# IWRL6432 register map
File version: 1.0
CPU: CM4 1.0, other endian, MPU, FPU, 3 interrupt priority bits
Registers are 32-bit, read-write, reset 0x0 unless marked. A register's access mark holds for its fields unless they carry their own. Offsets are from the block's base; [hi:lo] are bit positions; {n}, {i} and the like mark numbered series; 'fields as' and 'values as' point back to an identical list; <NAME> marks a mode.

## APP_CTRL (part 1 of 2)
Base 0x56060000
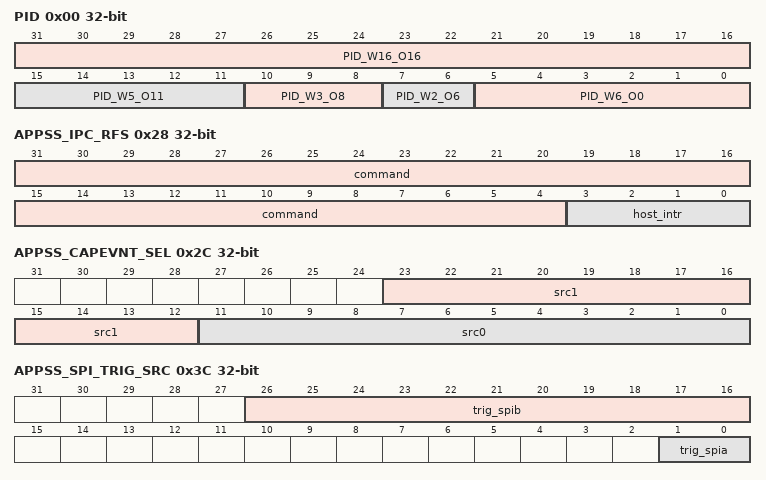
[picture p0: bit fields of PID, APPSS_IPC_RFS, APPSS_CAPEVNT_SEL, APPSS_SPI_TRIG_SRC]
0x00 PID
  [31:16] PID_W16_O16, [15:11] PID_W5_O11, [10:8] PID_W3_O8, [7:6] PID_W2_O6, [5:0] PID_W6_O0
0x04 HW_REG0
  [31:0] hwreg0 — [31:0] HW reserved Regsiter
0x08 HW_REG1
  [31:0] hwreg1 — [31:0] HW reserved Regsiter
0x0C PREVIOUS_NAME
  [31:0] hwreg2 — [31:0] HW reserved Regsiter
{0x4+4i} HW_REG{i} (i=3..7)
  [31:0] hwreg{i} — [31:0] HW reserved Regsiter
0x24 APPSS_SW_INT
  [3:0] pulse — [3:0] Write_pulse bit field: writing 1'b1 to each bit will trigger SW_INT<0-3> respectively to CM4.
0x28 APPSS_IPC_RFS
  [31:4] command — [31:4] Used by software to communicate commands and response. It is 7-bits per interrupt.
  [3:0] host_intr — [3:0] Write_pulse bit field: Writing 1'b1 to each bit will trigger HOST_INTR <0-3> respectively to CM3.
0x2C APPSS_CAPEVNT_SEL
  [23:12] src1 — [23:12] 5:0 : Selects the interrupt to route to RTI Capture event 1 6'd0 : MUXED_FECSS_CHIRPTIMER_CHIRP_START_AND_CHIRP_END 6'd1 : MUXED_FECSS_CHIRPTIMER_BURST_START_AND_BURST_END 6'd2 : FECSS_CHIRPTIMER_FRAME_END 6'd3 : FECSS_FRAMETIMER_FRAME_START 6'd4 : MUXED_FECSS_CHIRP_AVAIL_IRQ_AND_ADC_VALID_START_AND_SYNC_IN 6'd5 : MUXED_FECSS_FRAME_START_OFFSET_INTR_TIME1 6'd6 : FECSS_FRAME_START_OFFSET_INTR_TIME2 6'd7 : FECSS_FRAME_START_OFFSET_INTR_TIME3 6'd8 : FECSS_BURST_START_OFFSET_TIME 11:6: Selects the interrupt to route to WDT Capture event 1 6'd0 : MUXED_FECSS_CHIRPTIMER_CHIRP_START_AND_CHIRP_END 6'd1 : MUXED_FECSS_CHIRPTIMER_BURST_START_AND_BURST_END 6'd2 : FECSS_CHIRPTIMER_FRAME_END 6'd3 : FECSS_FRAMETIMER_FRAME_START 6'd4 : MUXED_FECSS_CHIRP_AVAIL_IRQ_AND_ADC_VALID_START_AND_SYNC_IN 6'd5 : MUXED_FECSS_FRAME_START_OFFSET_INTR_TIME1 6'd6 : FECSS_FRAME_START_OFFSET_INTR_TIME2 6'd7 : FECSS_FRAME_START_OFFSET_INTR_TIME3 6'd8 : FECSS_BURST_START_OFFSET_TIME 6'd9 : FECSS_IPC_RFS_FEC_INTR 1
  [11:0] src0 — [11:0] 5:0 : Selects the interrupt to route to RTI Capture event 0 6'd0 : FECSS_FRAME_START_OFFSET_INTR_TIME3 6'd1 : FECSS_FRAME_START_OFFSET_INTR_TIME2 6'd2 : FECSS_FRAME_START_OFFSET_INTR_TIME1 6'd3 : FECSS_FRAMETIMER_FRAME_START 6'd4 : LIN_INT1 6'd5 : LIN_INT0 6'd6 : MCAN_FE_INT7 6'd7 : MCAN_FE_INT1 6'd8 : MCAN_FE_INT2 6'd9 : MCAN_FE_INT3 6'd10 : MCAN_FE_INT4 6'd11 : MCAN_FE_INT5 6'd12 : MCAN_FE_INT6 6'd13 : MCAN_INT0 6'd14 : MCAN_INT1 6'd15 : SYNC_IN 11:6: Selects the interrupt to route to WDT Capture event 0 6'd0 : MUXED_FECSS_CHIRPTIMER_CHIRP_START_AND_CHIRP_END 6'd1 : MUXED_FECSS_CHIRPTIMER_BURST_START_AND_BURST_END 6'd2 : FECSS_CHIRPTIMER_FRAME_END 6'd3 : FECSS_FRAMETIMER_FRAME_START 6'd4 : MUXED_FECSS_CHIRP_AVAIL_IRQ_AND_ADC_VALID_START_AND_SYNC_IN 6'd5 : MUXED_FECSS_FRAME_START_OFFSET_INTR_TIME1 6'd6 : FECSS_FRAME_START_OFFSET_INTR_TIME2 6'd7 : FECSS_FRAME_START_OFFSET_INTR_TIME3 6'd8 : FECSS_BURST_START_OFFSET_TIME 6'd9 : FECSS_IPC_RFS_FEC_INTR 0
0x30 APPSS_DMA_REQ_SEL
  [31:0] select — [31:0] Reserved for R&D. Do not touch
0x34 APPSS_DMA1_REQ_SEL
  [31:0] select — [31:0] Reserved for R&D. Do not touch
0x38 APPSS_IRQ_REQ_SEL
  [31:0] select — [31:0] Configuration register APPSS_IRQ_REQ_SEL is used to select the interrupt for CM4. Below are the bit definitions 0 : 0x0 = Map 0th IRQ from compare block of RTI (RTI1) to IRQ43 : 0x1 = Map 0th IRQ from compare block of WDT (RTI2) to IRQ43 1 : 0x0 = Map 1st IRQ from compare block of RTI (RTI1) to IRQ44 : 0x1 = Map 1st IRQ from compare block of WDT (RTI2) to IRQ44 2 : 0x0 = Map 2nd IRQ from compare block of RTI (RTI1) to IRQ45 : 0x1 = Map 2nd IRQ from compare block of WDT (RTI2) to IRQ45 3 : 0x0 = Map 3rd IRQ from compare block of RTI (RTI1) to IRQ46 : 0x1 = Map 3rd IRQ from compare block of WDT (RTI2) to IRQ46 5:4 : 0x00 = Selects time base IRQ from RTI (RTI1) to IRQ47 : 0x01 = Selects time base IRQ from WDT (RTI2) to IRQ47 : 0x10 = Selects gpadc_ifm_done to IRQ47 : 0x11 = Reserved 7:6 : 0x00 = Selects capture event 0 of RTI to IRQ48 and Selects capture event 1 of IRQ from RTI to IRQ49 : 0x01 = Selects capture event 0 of WDT to IRQ48 and Selects capture event 1 of IRQ from WDT to IRQ49 : 0x10 = Selects PWM Interrupt 0 to IRQ48 and PWM Interrupt 1 to IRQ49 : 0x11 = Selects OVL_REQ of RTI (RTI1) to IRQ48 and OVL_REQ of WDT to IRQ49 8 : 0x0 = mcan_fe_int7 connected to IRQ29 : 0x1 = debugss txdata_available interrupt connected to IRQ29. 9 : 0x0 = Used for TPPCA trigger. Dma read interrupt of SPI1/A channel routed to TPCCA (DMA) trigger 62 : 0x1 = Used for TPPCA trigger. dma read interrupt of SPI2/B channel routed to TPCCA (DMA) trigger 62 10 : 0x0 = Used for TPPCA trigger. dma write interrupt of SPI1/A channel routed to TPCCA (DMA) trigger 63 : 0x1 = Used for TPPCA trigger. dma write interrupt of SPI2/B channel routed to TPCCA (DMA) trigger 63 11 : 0x0 = Timing Engine Chirptimer_chirp_start to IRQ30 : 0x1 = Timing Engine Chirptimer_chirp_end to IRQ30 12 : 0x0 = Timing Engine Chirptimer_burst_start to IRQ31 : 0x1 = Timing Engine Chirptimer_burst_end to IRQ31 14:13: 0x00 = chirp_avail_irq to IRQ34 : 0x01 = adc_valid_start to IRQ34 : 0x10 = SYNC_in to IRQ34 15 : Reserved 16 : 0x0 = mcan_fe_int6 connected to IRQ28 : 0x1 = spi2_int_req connected to IRQ28 18:17: 0x00 = DCC_DONE Interrupt connected to IRQ12 : 0x01 = CM4 LBIST Interrupt connected to IRQ12 : 0x10 = CM3 LBIST Interrupt connected to IRQ12 : 0x11 = TOP PBIST Interrupt connected to IRQ12 20:19: 0x00 = I2C_INT Interrupt connected to IRQ19 : 0x01 = CM4 LBIST Interrupt connected to IRQ19 : 0x10 = CM3 LBIST Interrupt connected to IRQ19 : 0x11 = TOP PBIST Interrupt connected to IRQ19 21 : 0x0 = APPSS_TPCC1_ERRAGG connected to IRQ16 : 0x1 = CTI_TRIGOUT2 connected to IRQ16 22 : 0x0 = APPSS_TPCC2_ERRAGG connected to IRQ18 : 0x1 = CTI_TRIGOUT3 connected to IRQ18
0x3C APPSS_SPI_TRIG_SRC
  [26:16] trig_spib — [26:16] RESERVED
  [1:0] trig_spia — [1:0] RESERVED
{0x34+0xC*i} APPSS_RAM{i}A_MEM_INIT (i=1..3)
  [0] mem_init — [0:0] Write_pulse bit field: Writing 1'b1 will start initialization of APPSS_RAM{i} partion0 bank. Value in each row is initialized to 0x0C_0000_0000
{0x38+0xC*i} APPSS_RAM{i}A_MEM_INIT_DONE (i=1..3)
  [0] mem_init_done — [0:0] This field will be high once initialization of APPSS_RAM{i} partion0 banks is finished. Writing '1' would clear the bit.
{0x3C+0xC*i} APPSS_RAM{i}A_MEM_INIT_STATUS (i=1..3)
  [0] mem_status — [0:0] 1'b0: No initialization is happening for APPSS_RAM{i} partion0 bank 1'b1: Initialization is in progress for APPSS_RAM{i} partion0 bank
0x64 HWASS_SHRD_RAM0_MEM_INIT
  [0] mem_init — [0:0] Write_pulse bit field: Writing 1'b1 will start initializing the HWASS Shared RAM parition0. Value in each row is initialized to 0x0
0x68 HWASS_SHRD_RAM0_MEM_INIT_DONE
  [0] mem_init_done — [0:0] This field will be high once intialization of HWASS Shared RAM parition0 is finished. Writing '1' would clear the bit
0x6C HWASS_SHRD_RAM0_MEM_INIT_STATUS
  [0] mem_status — [0:0] 1'b0: No initialization is happening for HWASS Shared RAM parition0 1'b1: Initialization is in progress for HWASS Shared RAM parition0
0x70 HWASS_SHRD_RAM1_MEM_INIT
  [0] mem_init — [0:0] Write_pulse bit field: Writing 1'b1 will start initializing the HWASS Shared RAM parition1. Value in each row is initialized to 0x0
0x74 HWASS_SHRD_RAM1_MEM_INIT_DONE
  [0] mem_init_done — [0:0] This field will be high once intialization of HWASS Shared RAM parition1 is finished. Writing '1' would clear the bit
0x78 HWASS_SHRD_RAM1_MEM_INIT_STATUS
  [0] mem_status — [0:0] 1'b0: No initialization is happening for HWASS Shared RAM parition1 1'b1: Initialization is in progress for HWASS Shared RAM parition1
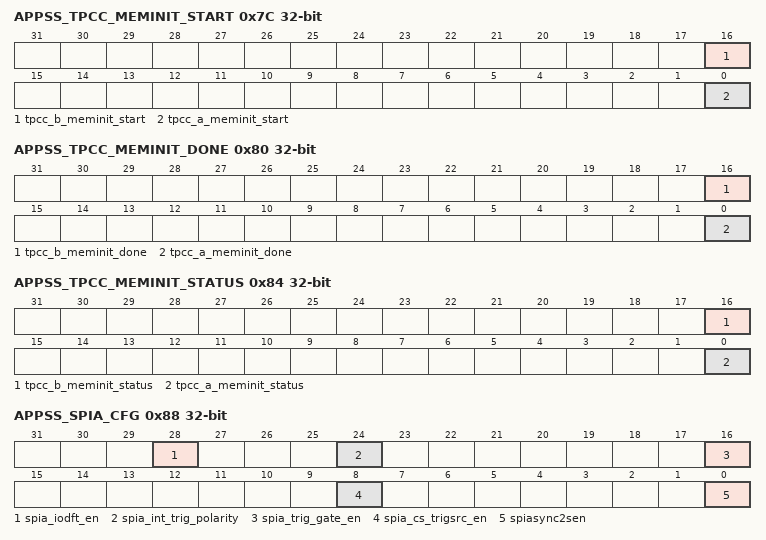
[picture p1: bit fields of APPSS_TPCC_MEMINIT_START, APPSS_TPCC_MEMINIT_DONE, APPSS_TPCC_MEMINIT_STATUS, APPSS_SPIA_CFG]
0x7C APPSS_TPCC_MEMINIT_START
  [16] tpcc_b_meminit_start — [16:16] Write_pulse bit field: Writing 1'b1 will start initializing the TPCCB
  [0] tpcc_a_meminit_start — [0:0] Write_pulse bit field: Writing 1'b1 will start initializing the TPCCA
0x80 APPSS_TPCC_MEMINIT_DONE
  [16] tpcc_b_meminit_done — [16:16] This field will be high once intialization of TPCCB is finished. Writing '1' would clear the bit
  [0] tpcc_a_meminit_done — [0:0] This field will be high once intialization of TPCCA is finished. Writing '1' would clear the bit
0x84 APPSS_TPCC_MEMINIT_STATUS
  [16] tpcc_b_meminit_status — [16:16] 1'b0: No initialization is happening for TPCCA 1'b1: Initialization is in progress for TPCCB
  [0] tpcc_a_meminit_status — [0:0] 1'b0: No initialization is happening for TPCCA 1'b1: Initialization is in progress for TPCCB
0x88 APPSS_SPIA_CFG
  [28] spia_iodft_en — [28:28] 1: Enable loop back of MOSI to MISO - Master mode Enable loop back of MISO to MOSI - Slave mode
  [24] spia_int_trig_polarity — [24:24] SPIA trigger source polarity select. 0 - Polarity 0, 1 -Polarity 1
  [16] spia_trig_gate_en — [16:16] When set the TRIGGER s are un-gated only when chip-select is active
  [8] spia_cs_trigsrc_en — [8:8] MIBSPIB CS Trigger SRC enable 1 : Use CS as trigger source
  [0] spiasync2sen — [0:0] Donot touch the field. Used as Tie-off for IP-config.
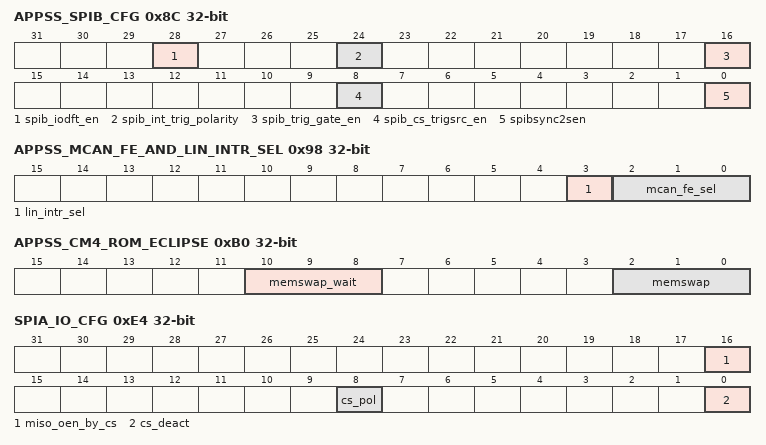
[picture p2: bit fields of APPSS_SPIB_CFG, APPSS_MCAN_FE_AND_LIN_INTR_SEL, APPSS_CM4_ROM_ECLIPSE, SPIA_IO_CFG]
0x8C APPSS_SPIB_CFG
  [28] spib_iodft_en — [28:28] 1: Enable loop back of MOSI to MISO - Master mode Enable loop back of MISO to MOSI - Slave mode
  [24] spib_int_trig_polarity — [24:24] SPIB trigger source polarity select. 0 - Polarity 0, 1 -Polarity 1
  [16] spib_trig_gate_en — [16:16] When set the TRIGGER s are un-gated only when chip-select is active
  [8] spib_cs_trigsrc_en — [8:8] MIBSPIB CS Trigger SRC enable 1 : Use CS as trigger source
  [0] spibsync2sen — [0:0] Donot touch the field. Used as Tie-off for IP-config.
0x90 APPSS_EPWM_CFG
  [31:0] epwm_config — [31:0] bit0: SW syncin for EPWM1 bit1: SW syncin for EPWM2 bit2: SW syncin for EPWM3 bit8:9 : select bits for EPWM1 '0' : external syncin '1' : reserved '2' : sw syncin '3' : reserved bit10:11 : select bits for EPWM2 '0' : external syncin '1' : chained from EPWM1 '2' : sw syncin '3' : reserved bit12:13 : select bits for EPWM3 '0' : external syncin '1' : chained from EPWM2 '2' : sw syncin '3' : reserved bit24:TBCLKEN for EPWM1 bit25:TBCLKEN for EPWM2 bit26:TBCLKEN for EPWM3
0x94 RESERVED
  [31:0] gio_config — [31:0] bit0 : writing '1' will slect negedge for pulse generation of GIO_PAD_INT0 to IRQ bit1 : writing '1' will slect negedge for pulse generation of GIO_PAD_INT1to IRQ bit2: writing '1' will slect negedge for pulse generation of GIO_PAD_INT2 to IRQ bit3 : writing '1' will slect negedge for pulse generation of GIO_PAD_INT3 to IRQ bit4 : writing '1' will slect negedge for pulse generation of GIO_PAD_INT4 to IRQ bit5 : writing '1' will slect negedge for pulse generation of GIO_PAD_INT5 to IRQ bit6 : writing '1' will slect negedge for pulse generation of GIO_PAD_INT6 to IRQ bit7 : writing '1' will slect negedge for pulse generation of GIO_PAD_INT7 to IRQ
0x98 APPSS_MCAN_FE_AND_LIN_INTR_SEL
  [3] lin_intr_sel — [3:3] Writing a value would select the LIN interrupt in combination with HW_SYNC_IN and CAN filter events for Frame timer 0 : 0th interrupt bit is selected 1 : 1st interrupt bit is selected
  [2:0] mcan_fe_sel — [2:0] Writing a value 'N' would select Nth filter interrupt combination with SYNC_IN(IO) for triggering timing engine Example: writing 3'd<1-7> selects MCAN_FE_INT<1-7> respectively
0x9C APPSS_MCANA_INT_CLR
  [31:0] mcan_int_clr — [31:0] Interrupt Clear for 32 MCANSS TX DMA interrupts. Writing 1'b1 to bit<0-31> clears interrupt source <0-31> respectively in MCANA
0xA0 APPSS_MCANA_INT_MASK
  [31:0] mcan_int_mask — [31:0] Interrupt Mask for 32 MCANSS TX DMA interrupts. Writing 1'b1 to bit<0-31> masks interrupt source <0-31> respectively in MCANA
0xA4 APPSS_MCANA_INT_STAT
  [31:0] mcan_int_status — [31:0] Interrupt status for 32 MCANSS TX DMA interrupts. 1'b1 in bit<0-31> gives pending status for interrupt <0-31> respectively in MCANA
0xA8 APPSS_CM4_GLOBAL_CONFIG
  [0] teinit — [0:0] Reserved
0xAC RESERVED1
  [31:0] res — [31:0] reserved
0xB0 APPSS_CM4_ROM_ECLIPSE
  [10:8] memswap_wait — [10:8] writing 3'b111 ensures ROM-Eclipsing happens only after CPU sys reset. Orelse it will be a immediate change.
  [2:0] memswap — [2:0] writing '111' ensures eclipsing of CPU_ROM immediately if memswap_wait is not set. If memswap_wait is set then ROM is eclipsed after CPU sys reset assertion.
0xB4 APPSS_CM4_STATUS_REG
  [0] memswap — [0:0] reading 1: confirms ROM is Eclipsed from with RAM for the CPU.
0xB8 APPSS_AHB_CTRL
  [0] cpu0_ahb_init — [0:0] Ti internal Register. Modifying this register is not recommended Signal decides whehter ahb interface is enabled or not.
{0xBC+4i} ESM_GATING{i} (i=0..3)
  [31:0] esm_gating — [31:0] bit3:0 : writing '000' will ungate the ESM_GRP2_ERROR_{8i} bit7:4 : writing '000' will ungate the ESM_GRP2_ERROR_{8i+1} bit31:28 : writing '000' will ungate the ESM_GRP2_ERROR_{8i+7}
{0xBC+4i} ESM_GATING{i} (i=4..7)
  [31:0] esm_gating — [31:0] bit3:0 : writing '000' will ungate the ESM_GRP3_ERROR_{8i-32} bit7:4 : writing '000' will ungate the ESM_GRP3_ERROR_{8i-31} bit31:28 : writing '000' will ungate the ESM_GRP3_ERROR_{8i-25}
0xDC APPSS_CM4_HALT
  [2:0] halt — [2:0] RESERVED
0xE0 APPSS_CM4_EVENT
  [2:0] cpu0_event — [2:0] Reserved Register for R & D
0xE4 SPIA_IO_CFG
  [16] miso_oen_by_cs — [16:16] RESERVED
  [8] cs_pol — [8:8] RESERVED
  [0] cs_deact — [0:0] RESERVED
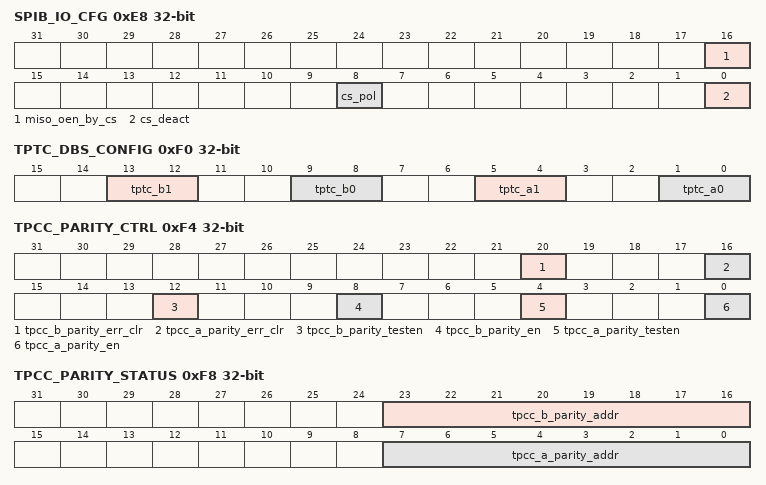
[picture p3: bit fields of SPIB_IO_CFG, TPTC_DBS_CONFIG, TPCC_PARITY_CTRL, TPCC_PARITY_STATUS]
0xE8 SPIB_IO_CFG
  fields as SPIA_IO_CFG
0xEC SPI_HOST_IRQ
  [0] host_irq — [0:0] RESERVED
0xF0 TPTC_DBS_CONFIG
  [13:12] tptc_b1 — [13:12] Default burst size tieoff value for TPTC_B1
  [9:8] tptc_b0 — [9:8] Default burst size tieoff value for TPTC_B0
  [5:4] tptc_a1 — [5:4] Default burst size tieoff value for TPTC_A1
  [1:0] tptc_a0 — [1:0] Default burst size tieoff value for TPTC_A0
0xF4 TPCC_PARITY_CTRL
  [20] tpcc_b_parity_err_clr — [20:20] Write pulse bit field: parity clear bit. Writing 1'b1 will clear the tpcc_b_parity_addr
  [16] tpcc_a_parity_err_clr — [16:16] Write pulse bit field: parity clear bit. Writing 1'b1 will clear the tpcc_a_parity_addr
  [12] tpcc_b_parity_testen — [12:12] parity test enable for tpcc b
  [8] tpcc_b_parity_en — [8:8] parity en for tpcc b
  [4] tpcc_a_parity_testen — [4:4] parity test enable for tpcc a
  [0] tpcc_a_parity_en — [0:0] writing 1'b1 enables parity for TPCC_A
0xF8 TPCC_PARITY_STATUS
  [23:16] tpcc_b_parity_addr — [23:16] address where parity error happened for tpccb
  [7:0] tpcc_a_parity_addr — [7:0] address where parity error happened for tpcca
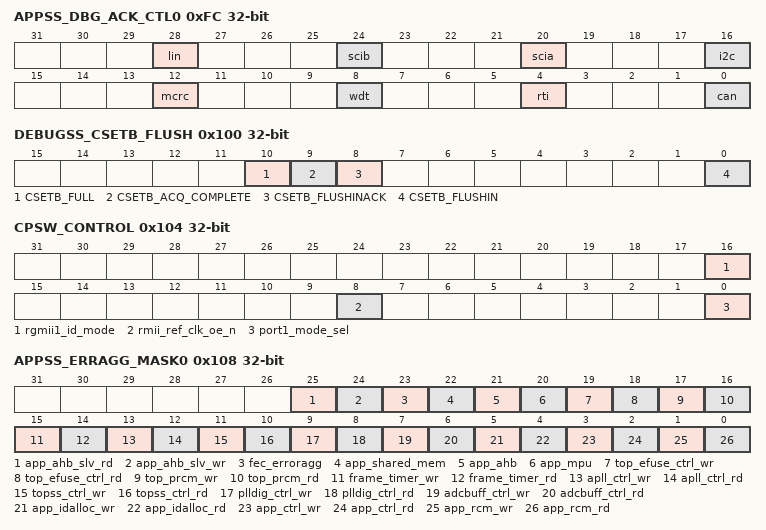
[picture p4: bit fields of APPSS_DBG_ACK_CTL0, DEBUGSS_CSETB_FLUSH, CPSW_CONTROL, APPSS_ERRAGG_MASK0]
0xFC APPSS_DBG_ACK_CTL0
  [28] lin — [28:28] Enable Suspend control for the peripheral. 0 :Peripheral not suspended along with processor 1: Peripehal Suspended along with procesor
  [24] scib — [24:24] Enable Suspend control for the peripheral. 0 :Peripheral not suspended along with processor 1: Peripehal Suspended along with procesor
  [20] scia — [20:20] Enable Suspend control for the peripheral. 0 :Peripheral not suspended along with processor 1: Peripehal Suspended along with procesor
  [16] i2c — [16:16] Enable Suspend control for the peripheral. 0 :Peripheral not suspended along with processor 1: Peripehal Suspended along with procesor
  [12] mcrc — [12:12] Enable Suspend control for the peripheral. 0 :Peripheral not suspended along with processor 1: Peripehal Suspended along with procesor
  [8] wdt — [8:8] Enable Suspend control for the peripheral. 0 :Peripheral not suspended along with processor 1: Peripehal Suspended along with procesor
  [4] rti — [4:4] Enable Suspend control for the peripheral. 0 :Peripheral not suspended along with processor 1: Peripehal Suspended along with procesor
  [0] can — [0:0] Enable Suspend control for the peripheral. 0 :Peripheral not suspended along with processor 1: Peripehal Suspended along with procesor
0x100 DEBUGSS_CSETB_FLUSH
  [10] CSETB_FULL — [10:10] RESERVED
  [9] CSETB_ACQ_COMPLETE — [9:9] RESERVED
  [8] CSETB_FLUSHINACK — [8:8] RESERVED
  [0] CSETB_FLUSHIN — [0:0] RESERVED
0x104 CPSW_CONTROL
  [16] rgmii1_id_mode — [16:16] Reserved
  [8] rmii_ref_clk_oe_n — [8:8] Reserved
  [0] port1_mode_sel — [0:0] Reserved
0x108 APPSS_ERRAGG_MASK0
  [25] app_ahb_slv_rd — [25:25] Mask Interrupt from AHB slaves to aggregated Interrupt APPSS_ACCESS_ERRAGG 1 : Interrupt is Masked 0 : Interrupt is Unmasked
  [24] app_ahb_slv_wr — [24:24] Mask Interrupt from AHB slaves to aggregated Interrupt APPSS_ACCESS_ERRAGG 1 : Interrupt is Masked 0 : Interrupt is Unmasked
  [23] fec_erroragg — [23:23] Mask Interrupt from FEC_ERRORAGG to aggregated Interrupt APPSS_ACCESS_ERRAGG 1 : Interrupt is Masked 0 : Interrupt is Unmasked
  [22] app_shared_mem — [22:22] Mask Interrupt from APP_SHARED_MEM to aggregated Interrupt APPSS_ACCESS_ERRAGG 1 : Interrupt is Masked 0 : Interrupt is Unmasked
  [21] app_ahb — [21:21] Mask Interrupt from APP_AHB to aggregated Interrupt APPSS_ACCESS_ERRAGG 1 : Interrupt is Masked 0 : Interrupt is Unmasked
  [20] app_mpu — [20:20] Mask Interrupt from APP_MPU to aggregated Interrupt APPSS_ACCESS_ERRAGG 1 : Interrupt is Masked 0 : Interrupt is Unmasked
  [19] top_efuse_ctrl_wr — [19:19] Mask Interrupt from TOP_EFUSE_CTRL to aggregated Interrupt APPSS_ACCESS_ERRAGG 1 : Interrupt is Masked 0 : Interrupt is Unmasked
  [18] top_efuse_ctrl_rd — [18:18] Mask Interrupt from FEC_ERRORAGG to aggregated Interrupt APPSS_ACCESS_ERRAGG 1 : Interrupt is Masked 0 : Interrupt is Unmasked
  [17] top_prcm_wr — [17:17] Mask Interrupt from TOP_PRCM to aggregated Interrupt APPSS_ACCESS_ERRAGG 1 : Interrupt is Masked 0 : Interrupt is Unmasked
  [16] top_prcm_rd — [16:16] Mask Interrupt from TOP_PRCM to aggregated Interrupt APPSS_ACCESS_ERRAGG 1 : Interrupt is Masked 0 : Interrupt is Unmasked
  [15] frame_timer_wr — [15:15] Mask Interrupt from FRAME_TIMER to aggregated Interrupt APPSS_ACCESS_ERRAGG 1 : Interrupt is Masked 0 : Interrupt is Unmasked
  [14] frame_timer_rd — [14:14] Mask Interrupt from FRAME_TIMER to aggregated Interrupt APPSS_ACCESS_ERRAGG 1 : Interrupt is Masked 0 : Interrupt is Unmasked
  [13] apll_ctrl_wr — [13:13] Mask Interrupt from APLL_CTRL to aggregated Interrupt APPSS_ACCESS_ERRAGG 1 : Interrupt is Masked 0 : Interrupt is Unmasked
  [12] apll_ctrl_rd — [12:12] Mask Interrupt from APLL_CTRL to aggregated Interrupt APPSS_ACCESS_ERRAGG 1 : Interrupt is Masked 0 : Interrupt is Unmasked
  [11] topss_ctrl_wr — [11:11] Mask Interrupt from TOPSS_CTRL to aggregated Interrupt APPSS_ACCESS_ERRAGG 1 : Interrupt is Masked 0 : Interrupt is Unmasked
  [10] topss_ctrl_rd — [10:10] Mask Interrupt from TOPSS_CTRL to aggregated Interrupt APPSS_ACCESS_ERRAGG 1 : Interrupt is Masked 0 : Interrupt is Unmasked
  [9] plldig_ctrl_wr — [9:9] Mask Interrupt from PLLDIG_CTRL to aggregated Interrupt APPSS_ACCESS_ERRAGG 1 : Interrupt is Masked 0 : Interrupt is Unmasked
  [8] plldig_ctrl_rd — [8:8] Mask Interrupt from PLLDIG_CTRL to aggregated Interrupt APPSS_ACCESS_ERRAGG 1 : Interrupt is Masked 0 : Interrupt is Unmasked
  [7] adcbuff_ctrl_wr — [7:7] Mask Interrupt from ADCBUFF_CTRL to aggregated Interrupt APPSS_ACCESS_ERRAGG 1 : Interrupt is Masked 0 : Interrupt is Unmasked
  [6] adcbuff_ctrl_rd — [6:6] Mask Interrupt from ADCBUFF_CTRL to aggregated Interrupt APPSS_ACCESS_ERRAGG 1 : Interrupt is Masked 0 : Interrupt is Unmasked
  [5] app_idalloc_wr — [5:5] Mask Interrupt from APP_IDALLOC to aggregated Interrupt APPSS_ACCESS_ERRAGG 1 : Interrupt is Masked 0 : Interrupt is Unmasked
  [4] app_idalloc_rd — [4:4] Mask Interrupt from APP_IDALLOC to aggregated Interrupt APPSS_ACCESS_ERRAGG 1 : Interrupt is Masked 0 : Interrupt is Unmasked
  [3] app_ctrl_wr — [3:3] Mask Interrupt from APP_CTRL to aggregated Interrupt APPSS_ACCESS_ERRAGG 1 : Interrupt is Masked 0 : Interrupt is Unmasked
  [2] app_ctrl_rd — [2:2] Mask Interrupt from APP_CTRL to aggregated Interrupt APPSS_ACCESS_ERRAGG 1 : Interrupt is Masked 0 : Interrupt is Unmasked
  [1] app_rcm_wr — [1:1] Mask Interrupt from APP_RCM to aggregated Interrupt APPSS_ACCESS_ERRAGG 1 : Interrupt is Masked 0 : Interrupt is Unmasked
  [0] app_rcm_rd — [0:0] Mask Interrupt from APP_RCM to aggregated Interrupt APPSS_ACCESS_ERRAGG 1 : Interrupt is Masked 0 : Interrupt is Unmasked
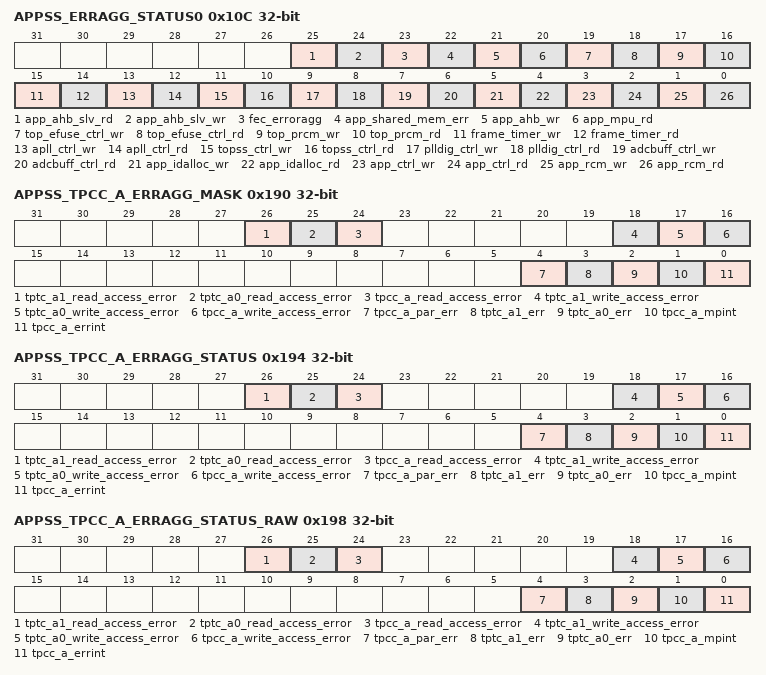
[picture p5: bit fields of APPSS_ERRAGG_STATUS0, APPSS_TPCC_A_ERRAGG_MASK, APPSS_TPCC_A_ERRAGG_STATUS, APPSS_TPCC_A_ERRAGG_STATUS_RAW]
0x10C APPSS_ERRAGG_STATUS0
  [25] app_ahb_slv_rd — [25:25] Status of Interrupt from AHB_SLAVE Set only if Interupt is unmasked in APPSS_ERRAGG_MASK0 Wrie 0x1 to clear this interrupt.
  [24] app_ahb_slv_wr — [24:24] Status of Interrupt from AHB_SLAVE Set only if Interupt is unmasked in APPSS_ERRAGG_MASK0 Wrie 0x1 to clear this interrupt.
  [23] fec_erroragg — [23:23] Status of Interrupt from FEC_ERRORAGG Set only if Interupt is unmasked in APPSS_ERRAGG_MASK0 Wrie 0x1 to clear this interrupt.
  [22] app_shared_mem_err — [22:22] Status of Interrupt from APP_SHARED_MEM Set only if Interupt is unmasked in APPSS_ERRAGG_MASK0 Wrie 0x1 to clear this interrupt.
  [21] app_ahb_wr — [21:21] Status of Interrupt from APP_AHB Set only if Interupt is unmasked in APPSS_ERRAGG_MASK0 Wrie 0x1 to clear this interrupt.
  [20] app_mpu_rd — [20:20] Status of Interrupt from APP_MPU Set only if Interupt is unmasked in APPSS_ERRAGG_MASK0 Wrie 0x1 to clear this interrupt.
  [19] top_efuse_ctrl_wr — [19:19] Status of Interrupt from TOP_EFUSE_CTRL Set only if Interupt is unmasked in APPSS_ERRAGG_MASK0 Wrie 0x1 to clear this interrupt.
  [18] top_efuse_ctrl_rd — [18:18] Status of Interrupt from TOP_EFUSE_CTRL Set only if Interupt is unmasked in APPSS_ERRAGG_MASK0 Wrie 0x1 to clear this interrupt.
  [17] top_prcm_wr — [17:17] Status of Interrupt from TOP_PRCM Set only if Interupt is unmasked in APPSS_ERRAGG_MASK0 Wrie 0x1 to clear this interrupt.
  [16] top_prcm_rd — [16:16] Status of Interrupt from TOP_PRCM Set only if Interupt is unmasked in APPSS_ERRAGG_MASK0 Wrie 0x1 to clear this interrupt.
  [15] frame_timer_wr — [15:15] Status of Interrupt from FRAME_TIMER Set only if Interupt is unmasked in APPSS_ERRAGG_MASK0 Wrie 0x1 to clear this interrupt.
  [14] frame_timer_rd — [14:14] Status of Interrupt from FRAME_TIMER Set only if Interupt is unmasked in APPSS_ERRAGG_MASK0 Wrie 0x1 to clear this interrupt.
  [13] apll_ctrl_wr — [13:13] Status of Interrupt from APLL_CTRL Set only if Interupt is unmasked in APPSS_ERRAGG_MASK0 Wrie 0x1 to clear this interrupt.
  [12] apll_ctrl_rd — [12:12] Status of Interrupt from APLL_CTRL Set only if Interupt is unmasked in APPSS_ERRAGG_MASK0 Wrie 0x1 to clear this interrupt.
  [11] topss_ctrl_wr — [11:11] Status of Interrupt from TOPSS_CTRL Set only if Interupt is unmasked in APPSS_ERRAGG_MASK0 Wrie 0x1 to clear this interrupt.
  [10] topss_ctrl_rd — [10:10] Status of Interrupt from TOPSS_CTRL Set only if Interupt is unmasked in APPSS_ERRAGG_MASK0 Wrie 0x1 to clear this interrupt.
  [9] plldig_ctrl_wr — [9:9] Status of Interrupt from PLLDIG_CTRL Set only if Interupt is unmasked in APPSS_ERRAGG_MASK0 Wrie 0x1 to clear this interrupt.
  [8] plldig_ctrl_rd — [8:8] Status of Interrupt from PLLDIG_CTRL Set only if Interupt is unmasked in APPSS_ERRAGG_MASK0 Wrie 0x1 to clear this interrupt.
  [7] adcbuff_ctrl_wr — [7:7] Status of Interrupt from ADCBUFF_CTRL Set only if Interupt is unmasked in APPSS_ERRAGG_MASK0 Wrie 0x1 to clear this interrupt.
  [6] adcbuff_ctrl_rd — [6:6] Status of Interrupt from ADCBUFF_CTRL Set only if Interupt is unmasked in APPSS_ERRAGG_MASK0 Wrie 0x1 to clear this interrupt.
  [5] app_idalloc_wr — [5:5] Status of Interrupt from APP_IDALLOC Set only if Interupt is unmasked in APPSS_ERRAGG_MASK0 Wrie 0x1 to clear this interrupt.
  [4] app_idalloc_rd — [4:4] Status of Interrupt from APP_IDALLOC Set only if Interupt is unmasked in APPSS_ERRAGG_MASK0 Wrie 0x1 to clear this interrupt.
  [3] app_ctrl_wr — [3:3] Status of Interrupt from APP_CTRL Set only if Interupt is unmasked in APPSS_ERRAGG_MASK0 Wrie 0x1 to clear this interrupt.
  [2] app_ctrl_rd — [2:2] Status of Interrupt from APP_CTRL Set only if Interupt is unmasked in APPSS_ERRAGG_MASK0 Wrie 0x1 to clear this interrupt.
  [1] app_rcm_wr — [1:1] Status of Interrupt from APP_RCM Set only if Interupt is unmasked in APPSS_ERRAGG_MASK0 Wrie 0x1 to clear this interrupt.
  [0] app_rcm_rd — [0:0] Status of Interrupt from APP_RCM Set only if Interupt is unmasked in APPSS_ERRAGG_MASK0 Wrie 0x1 to clear this interrupt.
0x190 APPSS_TPCC_A_ERRAGG_MASK
  [26] tptc_a1_read_access_error — [26:26] Mask Error from TPTC_A1 to aggregated Error TPCC_A_ERRAGG 1 : Error is Masked 0 : Error is Unmasked
  [25] tptc_a0_read_access_error — [25:25] Mask Error from TPTC_A0 to aggregated Error TPCC_A_ERRAGG 1 : Error is Masked 0 : Error is Unmasked
  [24] tpcc_a_read_access_error — [24:24] Mask Error from TPCC_A to aggregated Error TPCC_A_ERRAGG 1 : Error is Masked 0 : Error is Unmasked
  [18] tptc_a1_write_access_error — [18:18] Mask Error from TPTC_A1 to aggregated Error TPCC_A_ERRAGG 1 : Error is Masked 0 : Error is Unmasked
  [17] tptc_a0_write_access_error — [17:17] Mask Error from TPTC_A0 to aggregated Error TPCC_A_ERRAGG 1 : Error is Masked 0 : Error is Unmasked
  [16] tpcc_a_write_access_error — [16:16] Mask Error from TPCC_A to aggregated Error TPCC_A_ERRAGG 1 : Error is Masked 0 : Error is Unmasked
  [4] tpcc_a_par_err — [4:4] Mask Error from TPCC_A to aggregated Error TPCC_A_ERRAGG 1 : Error is Masked 0 : Error is Unmasked
  [3] tptc_a1_err — [3:3] Mask Error from TPTC_A1 to aggregated Error TPCC_A_ERRAGG 1 : Error is Masked 0 : Error is Unmasked
  [2] tptc_a0_err — [2:2] Mask Error from TPTC_A0 to aggregated Error TPCC_A_ERRAGG 1 : Error is Masked 0 : Error is Unmasked
  [1] tpcc_a_mpint — [1:1] Mask Error from TPCC_A to aggregated Error TPCC_A_ERRAGG 1 : Error is Masked 0 : Error is Unmasked
  [0] tpcc_a_errint — [0:0] Mask Error from TPCC_A to aggregated Error TPCC_A_ERRAGG 1 : Error is Masked 0 : Error is Unmasked
0x194 APPSS_TPCC_A_ERRAGG_STATUS
  [26] tptc_a1_read_access_error — [26:26] Status of Error from TPTC_A1. Set only if Interupt is unmasked in TPCC_A_ERRAGG_MASK Wrie 0x1 to clear this Error.
  [25] tptc_a0_read_access_error — [25:25] Status of Error from TPTC_A0. Set only if Interupt is unmasked in TPCC_A_ERRAGG_MASK Wrie 0x1 to clear this Error.
  [24] tpcc_a_read_access_error — [24:24] Status of Error from TPCC_A. Set only if Interupt is unmasked in TPCC_A_ERRAGG_MASK Wrie 0x1 to clear this Error.
  [18] tptc_a1_write_access_error — [18:18] Status of Error from TPTC_A1. Set only if Interupt is unmasked in TPCC_A_ERRAGG_MASK Wrie 0x1 to clear this Error.
  [17] tptc_a0_write_access_error — [17:17] Status of Error from TPTC_A0. Set only if Interupt is unmasked in TPCC_A_ERRAGG_MASK Wrie 0x1 to clear this Error.
  [16] tpcc_a_write_access_error — [16:16] Status of Error from TPCC_A. Set only if Interupt is unmasked in TPCC_A_ERRAGG_MASK Wrie 0x1 to clear this Error.
  [4] tpcc_a_par_err — [4:4] Status of Error from TPCC_A. Set only if Interupt is unmasked in TPCC_A_ERRAGG_MASK Wrie 0x1 to clear this Error.
  [3] tptc_a1_err — [3:3] Status of Error from TPTC_A1. Set only if Interupt is unmasked in TPCC_A_ERRAGG_MASK Wrie 0x1 to clear this Error.
  [2] tptc_a0_err — [2:2] Status of Error from TPTC_A0. Set only if Interupt is unmasked in TPCC_A_ERRAGG_MASK Wrie 0x1 to clear this Error.
  [1] tpcc_a_mpint — [1:1] Status of Error from TPCC_A. Set only if Interupt is unmasked in TPCC_A_ERRAGG_MASK Wrie 0x1 to clear this Error.
  [0] tpcc_a_errint — [0:0] Status of Error from TPCC_A. Set only if Interupt is unmasked in TPCC_A_ERRAGG_MASK Wrie 0x1 to clear this Error.
0x198 APPSS_TPCC_A_ERRAGG_STATUS_RAW
  [26] tptc_a1_read_access_error — [26:26] Raw Status of Error from TPTC_A1. Set irrespective if the Interupt is masked or unmasked in TPCC_A_ERRAGG_MASK
  [25] tptc_a0_read_access_error — [25:25] Raw Status of Error from TPTC_A0. Set irrespective if the Interupt is masked or unmasked in TPCC_A_ERRAGG_MASK
  [24] tpcc_a_read_access_error — [24:24] Raw Status of Error from TPCC_A. Set irrespective if the Interupt is masked or unmasked in TPCC_A_ERRAGG_MASK
  [18] tptc_a1_write_access_error — [18:18] Raw Status of Error from TPTC_A1. Set irrespective if the Interupt is masked or unmasked in TPCC_A_ERRAGG_MASK
  [17] tptc_a0_write_access_error — [17:17] Raw Status of Error from TPTC_A0. Set irrespective if the Interupt is masked or unmasked in TPCC_A_ERRAGG_MASK
  [16] tpcc_a_write_access_error — [16:16] Raw Status of Error from TPCC_A. Set irrespective if the Interupt is masked or unmasked in TPCC_A_ERRAGG_MASK
  [4] tpcc_a_par_err — [4:4] Raw Status of Error from TPCC_A. Set irrespective if the Interupt is masked or unmasked in TPCC_A_ERRAGG_MASK
  [3] tptc_a1_err — [3:3] Raw Status of Error from TPTC_A1. Set irrespective if the Interupt is masked or unmasked in TPCC_A_ERRAGG_MASK
  [2] tptc_a0_err — [2:2] Raw Status of Error from TPTC_A0. Set irrespective if the Interupt is masked or unmasked in TPCC_A_ERRAGG_MASK
  [1] tpcc_a_mpint — [1:1] Raw Status of Error from TPCC_A. Set irrespective if the Interupt is masked or unmasked in TPCC_A_ERRAGG_MASK
  [0] tpcc_a_errint — [0:0] Raw Status of Error from TPCC_A. Set irrespective if the Interupt is masked or unmasked in TPCC_A_ERRAGG_MASK
